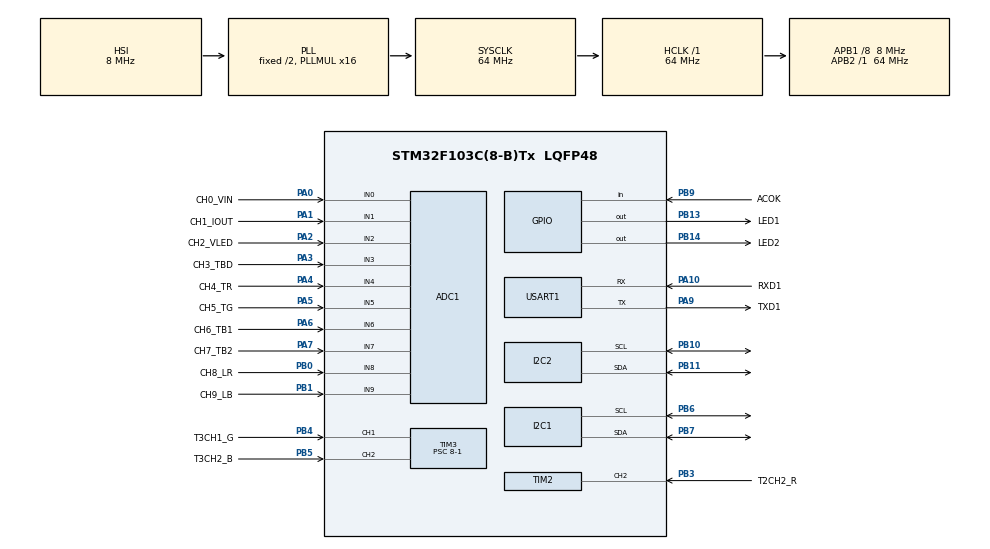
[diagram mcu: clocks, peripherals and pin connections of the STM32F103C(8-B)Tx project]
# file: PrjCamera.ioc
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ADC1.Channel-1\#ChannelRegularConversion=ADC_CHANNEL_0
ADC1.Channel-10\#ChannelRegularConversion=ADC_CHANNEL_9
ADC1.Channel-2\#ChannelRegularConversion=ADC_CHANNEL_1
ADC1.Channel-3\#ChannelRegularConversion=ADC_CHANNEL_2
ADC1.Channel-4\#ChannelRegularConversion=ADC_CHANNEL_3
ADC1.Channel-5\#ChannelRegularConversion=ADC_CHANNEL_4
ADC1.Channel-6\#ChannelRegularConversion=ADC_CHANNEL_5
ADC1.Channel-7\#ChannelRegularConversion=ADC_CHANNEL_6
ADC1.Channel-8\#ChannelRegularConversion=ADC_CHANNEL_7
ADC1.Channel-9\#ChannelRegularConversion=ADC_CHANNEL_8
ADC1.ContinuousConvMode=ENABLE
ADC1.NbrOfConversion=10
ADC1.NbrOfConversionFlag=1
ADC1.Rank-1\#ChannelRegularConversion=1
ADC1.Rank-10\#ChannelRegularConversion=10
ADC1.Rank-2\#ChannelRegularConversion=2
ADC1.Rank-3\#ChannelRegularConversion=3
ADC1.Rank-4\#ChannelRegularConversion=4
ADC1.Rank-5\#ChannelRegularConversion=5
ADC1.Rank-6\#ChannelRegularConversion=6
ADC1.Rank-7\#ChannelRegularConversion=7
ADC1.Rank-8\#ChannelRegularConversion=8
ADC1.Rank-9\#ChannelRegularConversion=9
ADC1.SamplingTime-1\#ChannelRegularConversion=ADC_SAMPLETIME_1CYCLE_5
ADC1.SamplingTime-10\#ChannelRegularConversion=ADC_SAMPLETIME_1CYCLE_5
ADC1.SamplingTime-2\#ChannelRegularConversion=ADC_SAMPLETIME_1CYCLE_5
ADC1.SamplingTime-3\#ChannelRegularConversion=ADC_SAMPLETIME_1CYCLE_5
ADC1.SamplingTime-4\#ChannelRegularConversion=ADC_SAMPLETIME_1CYCLE_5
ADC1.SamplingTime-5\#ChannelRegularConversion=ADC_SAMPLETIME_1CYCLE_5
ADC1.SamplingTime-6\#ChannelRegularConversion=ADC_SAMPLETIME_1CYCLE_5
ADC1.SamplingTime-7\#ChannelRegularConversion=ADC_SAMPLETIME_1CYCLE_5
ADC1.SamplingTime-8\#ChannelRegularConversion=ADC_SAMPLETIME_1CYCLE_5
ADC1.SamplingTime-9\#ChannelRegularConversion=ADC_SAMPLETIME_1CYCLE_5
ADC1.master=1
Dma.ADC1.0.Direction=DMA_PERIPH_TO_MEMORY
Dma.ADC1.0.Instance=DMA1_Channel1
Dma.ADC1.0.MemDataAlignment=DMA_MDATAALIGN_HALFWORD
Dma.ADC1.0.MemInc=DMA_MINC_ENABLE
Dma.ADC1.0.Mode=DMA_CIRCULAR
Dma.ADC1.0.PeriphDataAlignment=DMA_PDATAALIGN_HALFWORD
Dma.ADC1.0.PeriphInc=DMA_PINC_DISABLE
Dma.ADC1.0.Priority=DMA_PRIORITY_MEDIUM
Dma.I2C2_RX.1.Direction=DMA_PERIPH_TO_MEMORY
Dma.I2C2_RX.1.Instance=DMA1_Channel5
Dma.I2C2_RX.1.MemDataAlignment=DMA_MDATAALIGN_BYTE
Dma.I2C2_RX.1.MemInc=DMA_MINC_ENABLE
Dma.I2C2_RX.1.Mode=DMA_NORMAL
Dma.I2C2_RX.1.PeriphDataAlignment=DMA_PDATAALIGN_BYTE
Dma.I2C2_RX.1.PeriphInc=DMA_PINC_DISABLE
Dma.I2C2_RX.1.Priority=DMA_PRIORITY_LOW
Dma.I2C2_TX.2.Direction=DMA_MEMORY_TO_PERIPH
Dma.I2C2_TX.2.Instance=DMA1_Channel4
Dma.I2C2_TX.2.MemDataAlignment=DMA_MDATAALIGN_BYTE
Dma.I2C2_TX.2.MemInc=DMA_MINC_ENABLE
Dma.I2C2_TX.2.Mode=DMA_NORMAL
Dma.I2C2_TX.2.PeriphDataAlignment=DMA_PDATAALIGN_BYTE
Dma.I2C2_TX.2.PeriphInc=DMA_PINC_DISABLE
Dma.I2C2_TX.2.Priority=DMA_PRIORITY_LOW
Dma.Request0=ADC1
Dma.Request1=I2C2_RX
Dma.Request2=I2C2_TX
FREERTOS.Tasks01=TaskCmdHandleNa,0,64,TaskCmdHandle,Default,NULL,Dynamic,NULL,NULL;TaskDBGatherNam,-3,64,TaskDBGather,Default,NULL,Dynamic,NULL,NULL
FREERTOS.configENABLE_BACKWARD_COMPATIBILITY=0
FREERTOS.configMINIMAL_STACK_SIZE=64
FREERTOS.configTICK_RATE_HZ=100
FREERTOS.configTOTAL_HEAP_SIZE=2048
I2C2.I2C_Mode=I2C_Fast
I2C2.OwnAddress=0x20
Mcu.Family=STM32F1
Mcu.Name=STM32F103C(8-B)Tx
Mcu.Package=LQFP48
NVIC.ADC1_2_IRQn=true\:5\:0\:false\:false\:true\:true\:true\:true
NVIC.DMA1_Channel1_IRQn=true\:5\:0\:false\:false\:true\:true\:false\:true
NVIC.DMA1_Channel4_IRQn=true\:5\:0\:false\:false\:true\:true\:false\:true
NVIC.DMA1_Channel5_IRQn=true\:5\:0\:false\:false\:true\:true\:false\:true
NVIC.I2C2_ER_IRQn=true\:5\:0\:false\:false\:true\:true\:true\:true
NVIC.I2C2_EV_IRQn=true\:5\:0\:false\:false\:true\:true\:true\:true
NVIC.PriorityGroup=NVIC_PRIORITYGROUP_4
NVIC.TIM2_IRQn=true\:5\:0\:false\:false\:true\:true\:true\:true
NVIC.TIM3_IRQn=true\:5\:0\:false\:false\:true\:true\:true\:true
NVIC.USART1_IRQn=true\:5\:0\:false\:false\:true\:true\:true\:true
PA0-WKUP.GPIO_Label=CH0_VIN
PA0-WKUP.Signal=ADCx_IN0
PA1.GPIO_Label=CH1_IOUT
PA1.Signal=ADCx_IN1
PA10.GPIO_Label=RXD1
PA10.Mode=Asynchronous
PA10.Signal=USART1_RX
PA2.GPIO_Label=CH2_VLED
PA2.Signal=ADCx_IN2
PA3.GPIO_Label=CH3_TBD
PA3.Signal=ADCx_IN3
PA4.GPIO_Label=CH4_TR
PA4.Signal=ADCx_IN4
PA5.GPIO_Label=CH5_TG
PA5.Signal=ADCx_IN5
PA6.GPIO_Label=CH6_TB1
PA6.Signal=ADCx_IN6
PA7.GPIO_Label=CH7_TB2
PA7.Signal=ADCx_IN7
PA9.GPIO_Label=TXD1
PA9.Mode=Asynchronous
PA9.Signal=USART1_TX
PB0.GPIO_Label=CH8_LR
PB0.Signal=ADCx_IN8
PB1.GPIO_Label=CH9_LB
PB1.Signal=ADCx_IN9
PB10.Mode=I2C
PB10.Signal=I2C2_SCL
PB11.Mode=I2C
PB11.Signal=I2C2_SDA
PB13.GPIO_Label=LED1
PB13.GPIO_PuPd=GPIO_PULLUP
PB13.Signal=GPIO_Output
PB14.GPIO_Label=LED2
PB14.GPIO_PuPd=GPIO_PULLUP
PB14.Signal=GPIO_Output
PB3.GPIO_Label=T2CH2_R
PB3.Signal=S_TIM2_CH2
PB4.GPIO_Label=T3CH1_G
PB4.Signal=S_TIM3_CH1
PB5.GPIO_Label=T3CH2_B
PB5.Signal=S_TIM3_CH2
PB6.Mode=SMBus-two-wire-Interface
PB6.Signal=I2C1_SCL
PB7.Mode=SMBus-two-wire-Interface
PB7.Signal=I2C1_SDA
PB9.GPIO_Label=ACOK
PB9.GPIO_PuPd=GPIO_PULLUP
PB9.Signal=GPIO_Input
ProjectManager.HeapSize=0x200
ProjectManager.StackSize=0x400
ProjectManager.TargetToolchain=EWARM V8
RCC.ADCPresc=RCC_ADCPCLK2_DIV8
RCC.AHBFreq_Value=64000000
RCC.APB1CLKDivider=RCC_HCLK_DIV8
RCC.APB1Freq_Value=8000000
RCC.APB1TimFreq_Value=16000000
RCC.APB2Freq_Value=64000000
RCC.APB2TimFreq_Value=64000000
RCC.HCLKFreq_Value=64000000
RCC.PLLMUL=RCC_PLL_MUL16
RCC.SYSCLKFreq_VALUE=64000000
RCC.SYSCLKSource=RCC_SYSCLKSOURCE_PLLCLK
RCC.USBFreq_Value=64000000
SH.ADCx_IN0.0=ADC1_IN0,IN0
SH.ADCx_IN1.0=ADC1_IN1,IN1
SH.ADCx_IN2.0=ADC1_IN2,IN2
SH.ADCx_IN3.0=ADC1_IN3,IN3
SH.ADCx_IN4.0=ADC1_IN4,IN4
SH.ADCx_IN5.0=ADC1_IN5,IN5
SH.ADCx_IN6.0=ADC1_IN6,IN6
SH.ADCx_IN7.0=ADC1_IN7,IN7
SH.ADCx_IN8.0=ADC1_IN8,IN8
SH.ADCx_IN9.0=ADC1_IN9,IN9
SH.S_TIM2_CH2.0=TIM2_CH2,Input_Capture2_from_TI2
SH.S_TIM3_CH1.0=TIM3_CH1,Input_Capture1_from_TI1
SH.S_TIM3_CH2.0=TIM3_CH2,Input_Capture2_from_TI2
TIM2.Channel-Input_Capture2_from_TI2=TIM_CHANNEL_2
TIM2.ICFilter_CH2=8
TIM2.Period=0xFFFF
TIM2.Prescaler=8-1
TIM3.Channel-Input_Capture1_from_TI1=TIM_CHANNEL_1
TIM3.Channel-Input_Capture2_from_TI2=TIM_CHANNEL_2
TIM3.Period=0xFFFF
TIM3.Prescaler=8-1
USART1.VirtualMode=VM_ASYNC
VP_FREERTOS_VS_CMSIS_V1.Mode=CMSIS_V1
VP_IWDG_VS_IWDG.Mode=IWDG_Activate
VP_SYS_VS_ND.Mode=No_Debug
VP_TIM2_VS_ClockSourceINT.Mode=Internal
VP_TIM3_VS_ClockSourceINT.Mode=Internal
board=custom

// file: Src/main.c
/* USER CODE BEGIN Header */
/**
  ******************************************************************************
  * @file           : main.c
  * @brief          : Main program body
  ******************************************************************************
  * @attention
  *
  * <h2><center>&copy; Copyright (c) 2019 STMicroelectronics.
  * All rights reserved.</center></h2>
  *
  * This software component is licensed by ST under Ultimate Liberty license
  * SLA0044, the "License"; You may not use this file except in compliance with
  * the License. You may obtain a copy of the License at:
  *                             www.st.com/SLA0044
  *
  ******************************************************************************
  */
/* USER CODE END Header */

#include <stdio.h>
#include "main.h"
#include "cmsis_os.h"
#include "userTask.h"
#include "sysdb.h"
#include "UsartDriver.h"

ADC_HandleTypeDef hadc1;
DMA_HandleTypeDef hdma_adc1;

I2C_HandleTypeDef hi2c1;
I2C_HandleTypeDef hi2c2;
DMA_HandleTypeDef hdma_i2c1_tx;
DMA_HandleTypeDef hdma_i2c1_rx;
DMA_HandleTypeDef hdma_i2c2_rx;
DMA_HandleTypeDef hdma_i2c2_tx;

TIM_HandleTypeDef htim2;
TIM_HandleTypeDef htim3;

UART_HandleTypeDef huart1;

DMA_HandleTypeDef hdma_usart1_tx;

#ifdef IWDG_ENABLE
IWDG_HandleTypeDef hiwdg;
#endif

static void MX_GPIO_Init(void);
static void MX_ADC1_Init(void);
static void MX_I2C1_Init(void);
static void MX_I2C2_Init(void);
static void MX_TIM2_Init(void);
static void MX_TIM3_Init(void);
static void MX_USART1_UART_Init(void);
static void MX_DMA_Init(void);
#ifdef IWDG_ENABLE
static void MX_IWDG_Init(void);
#endif

void SystemClock_Config(void);
void TaskCmdHandle(void const * argument);
void TaskDBGather(void const * argument);
/* USER CODE BEGIN PFP */

/* Private user code ---------------------------------------------------------*/
/* USER CODE BEGIN 0 */
#ifdef __GNUC__
/* With GCC, small printf (option LD Linker->Libraries->Small printf
   set to 'Yes') calls __io_putchar() */
#define PUTCHAR_PROTOTYPE int __io_putchar(int ch)
#else
#define PUTCHAR_PROTOTYPE int fputc(int ch, FILE *f)
#endif /* __GNUC__ */
/* USER CODE END 0 */

/**
  * @brief  Retargets the C library printf function to the USART.
  * @param  None
  * @retval None
  */
PUTCHAR_PROTOTYPE
{
    /* Place your implementation of fputc here */
    /* e.g. write a character to the USART1 and Loop until the end of transmission */
    HAL_UART_Transmit(&huart1, (uint8_t *)&ch, 1, 0xFFFF);
    return ch;
}
/* USER CODE END PFP */

/* USER CODE BEGIN 0 */
#ifdef __GNUC__
/* With GCC, small printf (option LD Linker->Libraries->Small printf
   set to 'Yes') calls __io_putchar() */
#define PUTCHAR_PROTOTYPE int __io_putchar(int ch)
#else
#define PUTCHAR_PROTOTYPE int fputc(int ch, FILE *f)
#endif /* __GNUC__ */
/* USER CODE END 0 */

void _Error_Handler(char *file, int line)
{

  while(1)
  {
  }

}

int main(void)
{

  /* MCU Configuration--------------------------------------------------------*/

  /* Reset of all peripherals, Initializes the Flash interface and the Systick. */
  HAL_Init();

  /* Configure the system clock */
  SystemClock_Config();

  /* Initialize all configured peripherals */
  MX_GPIO_Init();

  MX_DMA_Init();

  MX_ADC1_Init();
  MX_I2C1_Init();
  MX_I2C2_Init();
#ifdef IWDG_ENABLE
  MX_IWDG_Init();
#endif
  MX_TIM2_Init();
  MX_TIM3_Init();
  MX_USART1_UART_Init();
  /* USER CODE BEGIN 2 */

  BQ24725_Flash_Already();

  /* USER CODE END 2 */

    CreateUserTask();

  /* Start scheduler */
  osKernelStart();

  /* We should never get here as control is now taken by the scheduler */

  /* Infinite loop */
  while (1)
  {

  }
}

void SystemClock_Config(void)
{
  RCC_OscInitTypeDef RCC_OscInitStruct = {0};
  RCC_ClkInitTypeDef RCC_ClkInitStruct = {0};
  RCC_PeriphCLKInitTypeDef PeriphClkInit = {0};

  /** Initializes the CPU, AHB and APB busses clocks
  */
  RCC_OscInitStruct.OscillatorType = RCC_OSCILLATORTYPE_HSI|RCC_OSCILLATORTYPE_LSI;
  RCC_OscInitStruct.HSIState = RCC_HSI_ON;
  RCC_OscInitStruct.HSICalibrationValue = RCC_HSICALIBRATION_DEFAULT;
  RCC_OscInitStruct.LSIState = RCC_LSI_ON;
  RCC_OscInitStruct.PLL.PLLState = RCC_PLL_ON;
  RCC_OscInitStruct.PLL.PLLSource = RCC_PLLSOURCE_HSI_DIV2;
  RCC_OscInitStruct.PLL.PLLMUL = RCC_PLL_MUL16;
  if (HAL_RCC_OscConfig(&RCC_OscInitStruct) != HAL_OK)
  {
    Error_Handler();
  }
  /** Initializes the CPU, AHB and APB busses clocks
  */
  RCC_ClkInitStruct.ClockType = RCC_CLOCKTYPE_HCLK|RCC_CLOCKTYPE_SYSCLK
                              |RCC_CLOCKTYPE_PCLK1|RCC_CLOCKTYPE_PCLK2;
  RCC_ClkInitStruct.SYSCLKSource = RCC_SYSCLKSOURCE_PLLCLK;
  RCC_ClkInitStruct.AHBCLKDivider = RCC_SYSCLK_DIV1;
  RCC_ClkInitStruct.APB1CLKDivider = RCC_HCLK_DIV8;
  RCC_ClkInitStruct.APB2CLKDivider = RCC_HCLK_DIV1;

  if (HAL_RCC_ClockConfig(&RCC_ClkInitStruct, FLASH_LATENCY_2) != HAL_OK)
  {
    Error_Handler();
  }
  PeriphClkInit.PeriphClockSelection = RCC_PERIPHCLK_ADC;
  PeriphClkInit.AdcClockSelection = RCC_ADCPCLK2_DIV8;
  if (HAL_RCCEx_PeriphCLKConfig(&PeriphClkInit) != HAL_OK)
  {
    Error_Handler();
  }
}

static void MX_ADC1_Init(void)
{

  ADC_ChannelConfTypeDef sConfig = {0};

  /** Common config
  */
  hadc1.Instance = ADC1;
  hadc1.Init.ScanConvMode = ADC_SCAN_ENABLE;
  hadc1.Init.ContinuousConvMode = ENABLE;
  hadc1.Init.DiscontinuousConvMode = DISABLE;
  hadc1.Init.ExternalTrigConv = ADC_SOFTWARE_START;
  hadc1.Init.DataAlign = ADC_DATAALIGN_RIGHT;
  hadc1.Init.NbrOfConversion = 10;
  if (HAL_ADC_Init(&hadc1) != HAL_OK)
  {
    Error_Handler();
  }
  /** Configure Regular Channel
  */
  sConfig.Channel = ADC_CHANNEL_0;
  sConfig.Rank = ADC_REGULAR_RANK_1;
  sConfig.SamplingTime = ADC_SAMPLETIME_1CYCLE_5;
  if (HAL_ADC_ConfigChannel(&hadc1, &sConfig) != HAL_OK)
  {
    Error_Handler();
  }
  /** Configure Regular Channel
  */
  sConfig.Channel = ADC_CHANNEL_1;
  sConfig.Rank = ADC_REGULAR_RANK_2;
  if (HAL_ADC_ConfigChannel(&hadc1, &sConfig) != HAL_OK)
  {
    Error_Handler();
  }
  /** Configure Regular Channel
  */
  sConfig.Channel = ADC_CHANNEL_2;
  sConfig.Rank = ADC_REGULAR_RANK_3;
  if (HAL_ADC_ConfigChannel(&hadc1, &sConfig) != HAL_OK)
  {
    Error_Handler();
  }
  /** Configure Regular Channel
  */
  sConfig.Channel = ADC_CHANNEL_3;
  sConfig.Rank = ADC_REGULAR_RANK_4;
  if (HAL_ADC_ConfigChannel(&hadc1, &sConfig) != HAL_OK)
  {
    Error_Handler();
  }
  /** Configure Regular Channel
  */
  sConfig.Channel = ADC_CHANNEL_4;
  sConfig.Rank = ADC_REGULAR_RANK_5;
  if (HAL_ADC_ConfigChannel(&hadc1, &sConfig) != HAL_OK)
  {
    Error_Handler();
  }
  /** Configure Regular Channel
  */
  sConfig.Channel = ADC_CHANNEL_5;
  sConfig.Rank = ADC_REGULAR_RANK_6;
  if (HAL_ADC_ConfigChannel(&hadc1, &sConfig) != HAL_OK)
  {
    Error_Handler();
  }
  /** Configure Regular Channel
  */
  sConfig.Channel = ADC_CHANNEL_6;
  sConfig.Rank = ADC_REGULAR_RANK_7;
  if (HAL_ADC_ConfigChannel(&hadc1, &sConfig) != HAL_OK)
  {
    Error_Handler();
  }
  /** Configure Regular Channel
  */
  sConfig.Channel = ADC_CHANNEL_7;
  sConfig.Rank = ADC_REGULAR_RANK_8;
  if (HAL_ADC_ConfigChannel(&hadc1, &sConfig) != HAL_OK)
  {
    Error_Handler();
  }
  /** Configure Regular Channel
  */
  sConfig.Channel = ADC_CHANNEL_8;
  sConfig.Rank = ADC_REGULAR_RANK_9;
  if (HAL_ADC_ConfigChannel(&hadc1, &sConfig) != HAL_OK)
  {
    Error_Handler();
  }
  /** Configure Regular Channel
  */
  sConfig.Channel = ADC_CHANNEL_9;
  sConfig.Rank = ADC_REGULAR_RANK_10;
  if (HAL_ADC_ConfigChannel(&hadc1, &sConfig) != HAL_OK)
  {
    Error_Handler();
  }

}

static void MX_I2C1_Init(void)
{

  hi2c1.Instance = I2C1;
  hi2c1.Init.ClockSpeed = 50000;
  hi2c1.Init.DutyCycle = I2C_DUTYCYCLE_2;
  hi2c1.Init.OwnAddress1 = 32;
  hi2c1.Init.AddressingMode = I2C_ADDRESSINGMODE_7BIT;
  hi2c1.Init.DualAddressMode = I2C_DUALADDRESS_DISABLE;
  hi2c1.Init.OwnAddress2 = 0;
  hi2c1.Init.GeneralCallMode = I2C_GENERALCALL_DISABLE;
  hi2c1.Init.NoStretchMode = I2C_NOSTRETCH_DISABLE;
  if (HAL_I2C_Init(&hi2c1) != HAL_OK)
  {
    Error_Handler();
  }

}

static void MX_I2C2_Init(void)
{

  hi2c2.Instance = I2C2;
  hi2c2.Init.ClockSpeed = 100000;
  hi2c2.Init.DutyCycle = I2C_DUTYCYCLE_2;
  hi2c2.Init.OwnAddress1 = 64;
  hi2c2.Init.AddressingMode = I2C_ADDRESSINGMODE_7BIT;
  hi2c2.Init.DualAddressMode = I2C_DUALADDRESS_DISABLE;
  hi2c2.Init.OwnAddress2 = 0;
  hi2c2.Init.GeneralCallMode = I2C_GENERALCALL_DISABLE;
  hi2c2.Init.NoStretchMode = I2C_NOSTRETCH_DISABLE;
  if (HAL_I2C_Init(&hi2c2) != HAL_OK)
  {
    Error_Handler();
  }

}

#ifdef IWDG_ENABLE
static void MX_IWDG_Init(void)
{

  hiwdg.Instance = IWDG;
  hiwdg.Init.Prescaler = IWDG_PRESCALER_4;
  hiwdg.Init.Reload = 4095;
  if (HAL_IWDG_Init(&hiwdg) != HAL_OK)
  {
    Error_Handler();
  }

}
#endif

static void MX_TIM2_Init(void)
{

  TIM_ClockConfigTypeDef sClockSourceConfig = {0};
  TIM_MasterConfigTypeDef sMasterConfig = {0};
  TIM_IC_InitTypeDef sConfigIC = {0};

  htim2.Instance = TIM2;
  htim2.Init.Prescaler = 8-1;
  htim2.Init.CounterMode = TIM_COUNTERMODE_UP;
  htim2.Init.Period = 0xFFFF;
  htim2.Init.ClockDivision = TIM_CLOCKDIVISION_DIV1;
  htim2.Init.AutoReloadPreload = TIM_AUTORELOAD_PRELOAD_DISABLE;
  if (HAL_TIM_Base_Init(&htim2) != HAL_OK)
  {
    Error_Handler();
  }
  sClockSourceConfig.ClockSource = TIM_CLOCKSOURCE_INTERNAL;
  if (HAL_TIM_ConfigClockSource(&htim2, &sClockSourceConfig) != HAL_OK)
  {
    Error_Handler();
  }
  if (HAL_TIM_IC_Init(&htim2) != HAL_OK)
  {
    Error_Handler();
  }
  sMasterConfig.MasterOutputTrigger = TIM_TRGO_RESET;
  sMasterConfig.MasterSlaveMode = TIM_MASTERSLAVEMODE_DISABLE;
  if (HAL_TIMEx_MasterConfigSynchronization(&htim2, &sMasterConfig) != HAL_OK)
  {
    Error_Handler();
  }
  sConfigIC.ICPolarity = TIM_INPUTCHANNELPOLARITY_RISING;
  sConfigIC.ICSelection = TIM_ICSELECTION_DIRECTTI;
  sConfigIC.ICPrescaler = TIM_ICPSC_DIV1;
  sConfigIC.ICFilter = 8;
  if (HAL_TIM_IC_ConfigChannel(&htim2, &sConfigIC, TIM_CHANNEL_2) != HAL_OK)
  {
    Error_Handler();
  }

}

static void MX_TIM3_Init(void)
{

  TIM_ClockConfigTypeDef sClockSourceConfig = {0};
  TIM_MasterConfigTypeDef sMasterConfig = {0};
  TIM_IC_InitTypeDef sConfigIC = {0};

  htim3.Instance = TIM3;
  htim3.Init.Prescaler = 8-1;
  htim3.Init.CounterMode = TIM_COUNTERMODE_UP;
  htim3.Init.Period = 0xFFFF;
  htim3.Init.ClockDivision = TIM_CLOCKDIVISION_DIV1;
  htim3.Init.AutoReloadPreload = TIM_AUTORELOAD_PRELOAD_DISABLE;
  if (HAL_TIM_Base_Init(&htim3) != HAL_OK)
  {
    Error_Handler();
  }
  sClockSourceConfig.ClockSource = TIM_CLOCKSOURCE_INTERNAL;
  if (HAL_TIM_ConfigClockSource(&htim3, &sClockSourceConfig) != HAL_OK)
  {
    Error_Handler();
  }
  if (HAL_TIM_IC_Init(&htim3) != HAL_OK)
  {
    Error_Handler();
  }
  sMasterConfig.MasterOutputTrigger = TIM_TRGO_RESET;
  sMasterConfig.MasterSlaveMode = TIM_MASTERSLAVEMODE_DISABLE;
  if (HAL_TIMEx_MasterConfigSynchronization(&htim3, &sMasterConfig) != HAL_OK)
  {
    Error_Handler();
  }
  sConfigIC.ICPolarity = TIM_INPUTCHANNELPOLARITY_RISING;
  sConfigIC.ICSelection = TIM_ICSELECTION_DIRECTTI;
  sConfigIC.ICPrescaler = TIM_ICPSC_DIV1;
  sConfigIC.ICFilter = 0;
  if (HAL_TIM_IC_ConfigChannel(&htim3, &sConfigIC, TIM_CHANNEL_1) != HAL_OK)
  {
    Error_Handler();
  }
  if (HAL_TIM_IC_ConfigChannel(&htim3, &sConfigIC, TIM_CHANNEL_2) != HAL_OK)
  {
    Error_Handler();
  }

}

static void MX_USART1_UART_Init(void)
{

  huart1.Instance = USART1;
  huart1.Init.BaudRate = 115200;
  huart1.Init.WordLength = UART_WORDLENGTH_8B;
  huart1.Init.StopBits = UART_STOPBITS_1;
  huart1.Init.Parity = UART_PARITY_NONE;
  huart1.Init.Mode = UART_MODE_TX_RX;
  huart1.Init.HwFlowCtl = UART_HWCONTROL_NONE;
  huart1.Init.OverSampling = UART_OVERSAMPLING_16;
  if (HAL_UART_Init(&huart1) != HAL_OK)
  {
    Error_Handler();
  }

}

static void MX_DMA_Init(void)
{
  /* DMA controller clock enable */
  __HAL_RCC_DMA1_CLK_ENABLE();

  /* DMA interrupt init */
#ifdef ENABLE_ADC_DMA
  /* DMA1_Channel1_IRQn interrupt configuration */
  HAL_NVIC_SetPriority(DMA1_Channel1_IRQn, 5, 0);//ADC1
  HAL_NVIC_EnableIRQ(DMA1_Channel1_IRQn);
#endif

#ifdef ENABLE_I2C2_TX_DMA
  /* DMA1_Channel4_IRQn interrupt configuration */
  HAL_NVIC_SetPriority(DMA1_Channel4_IRQn, 5, 0);//I2C2_TX
  HAL_NVIC_EnableIRQ(DMA1_Channel4_IRQn);
#endif

#ifdef ENABLE_I2C2_RX_DMA
  /* DMA1_Channel5_IRQn interrupt configuration */
  HAL_NVIC_SetPriority(DMA1_Channel5_IRQn, 5, 0);//I2C2_RX
  HAL_NVIC_EnableIRQ(DMA1_Channel5_IRQn);
#endif

#ifdef ENABLE_I2C1_TX_DMA
  /* DMA1_Channel6_IRQn interrupt configuration */
  HAL_NVIC_SetPriority(DMA1_Channel6_IRQn, 5, 0);//I2C1_TX
  HAL_NVIC_EnableIRQ(DMA1_Channel6_IRQn);
#endif

#ifdef ENABLE_I2C2_RX_DMA
  /* DMA1_Channel7_IRQn interrupt configuration */
  HAL_NVIC_SetPriority(DMA1_Channel7_IRQn, 5, 0);//I2C1_RX
  HAL_NVIC_EnableIRQ(DMA1_Channel7_IRQn);
#endif
}

static void MX_GPIO_Init(void)
{
  GPIO_InitTypeDef GPIO_InitStruct = {0};

  /* GPIO Ports Clock Enable */
  __HAL_RCC_GPIOA_CLK_ENABLE();
  __HAL_RCC_GPIOB_CLK_ENABLE();

  /*Configure GPIO pin Output Level */
  HAL_GPIO_WritePin(GPIOB, LED1_Pin|LED2_Pin, GPIO_PIN_RESET);

  /*Configure GPIO pins : LED1_Pin LED2_Pin */
  GPIO_InitStruct.Pin = LED1_Pin|LED2_Pin;
  GPIO_InitStruct.Mode = GPIO_MODE_OUTPUT_PP;
  GPIO_InitStruct.Pull = GPIO_PULLUP;
  GPIO_InitStruct.Speed = GPIO_SPEED_FREQ_LOW;
  HAL_GPIO_Init(GPIOB, &GPIO_InitStruct);

  /*Configure GPIO pin : ACOK_Pin */
  GPIO_InitStruct.Pin = ACOK_Pin;
  GPIO_InitStruct.Mode = GPIO_MODE_INPUT;
  GPIO_InitStruct.Pull = GPIO_PULLUP;
  HAL_GPIO_Init(ACOK_GPIO_Port, &GPIO_InitStruct);

}

void Error_Handler(void)
{
}

/************************ (C) COPYRIGHT STMicroelectronics *****END OF FILE****/
